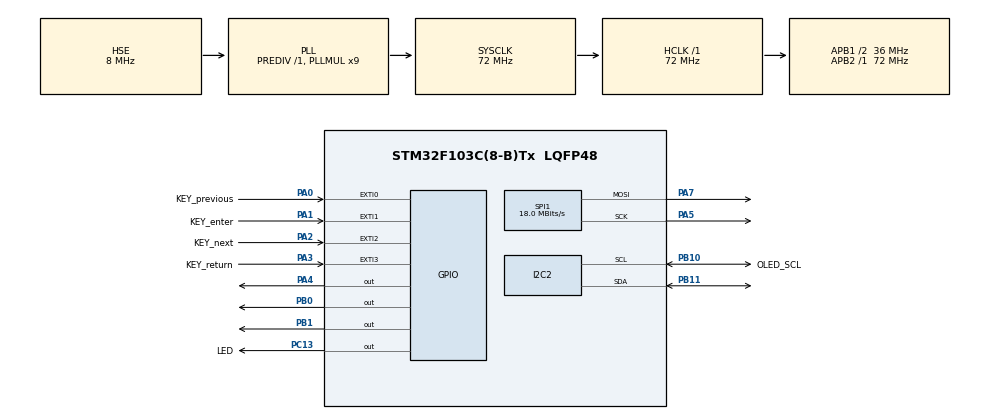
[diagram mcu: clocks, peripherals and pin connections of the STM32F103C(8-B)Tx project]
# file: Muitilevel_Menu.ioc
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Dma.I2C2_TX.1.Direction=DMA_MEMORY_TO_PERIPH
Dma.I2C2_TX.1.Instance=DMA1_Channel4
Dma.I2C2_TX.1.MemDataAlignment=DMA_MDATAALIGN_BYTE
Dma.I2C2_TX.1.MemInc=DMA_MINC_ENABLE
Dma.I2C2_TX.1.Mode=DMA_NORMAL
Dma.I2C2_TX.1.PeriphDataAlignment=DMA_PDATAALIGN_BYTE
Dma.I2C2_TX.1.PeriphInc=DMA_PINC_DISABLE
Dma.I2C2_TX.1.Priority=DMA_PRIORITY_LOW
Dma.Request0=SPI1_TX
Dma.Request1=I2C2_TX
Dma.SPI1_TX.0.Direction=DMA_MEMORY_TO_PERIPH
Dma.SPI1_TX.0.Instance=DMA1_Channel3
Dma.SPI1_TX.0.MemDataAlignment=DMA_MDATAALIGN_BYTE
Dma.SPI1_TX.0.MemInc=DMA_MINC_ENABLE
Dma.SPI1_TX.0.Mode=DMA_NORMAL
Dma.SPI1_TX.0.PeriphDataAlignment=DMA_PDATAALIGN_BYTE
Dma.SPI1_TX.0.PeriphInc=DMA_PINC_DISABLE
Dma.SPI1_TX.0.Priority=DMA_PRIORITY_LOW
I2C2.I2C_Mode=I2C_Fast
Mcu.Family=STM32F1
Mcu.Name=STM32F103C(8-B)Tx
Mcu.Package=LQFP48
NVIC.DMA1_Channel3_IRQn=true\:0\:0\:false\:false\:true\:false\:true\:true
NVIC.DMA1_Channel4_IRQn=true\:0\:0\:false\:false\:true\:false\:true\:true
NVIC.EXTI0_IRQn=true\:15\:0\:true\:false\:true\:true\:true\:true
NVIC.EXTI1_IRQn=true\:15\:0\:true\:false\:true\:true\:true\:true
NVIC.EXTI2_IRQn=true\:15\:0\:true\:false\:true\:true\:true\:true
NVIC.EXTI3_IRQn=true\:15\:0\:true\:false\:true\:true\:true\:true
NVIC.I2C2_ER_IRQn=true\:0\:0\:false\:false\:true\:true\:true\:true
NVIC.I2C2_EV_IRQn=true\:0\:0\:true\:false\:true\:true\:true\:true
NVIC.PriorityGroup=NVIC_PRIORITYGROUP_4
NVIC.SPI1_IRQn=true\:0\:0\:false\:false\:true\:true\:true\:true
PA0-WKUP.GPIO_Label=KEY_previous
PA0-WKUP.GPIO_ModeDefaultEXTI=GPIO_MODE_IT_FALLING
PA0-WKUP.GPIO_PuPd=GPIO_PULLUP
PA0-WKUP.Signal=GPXTI0
PA1.GPIO_Label=KEY_enter
PA1.GPIO_ModeDefaultEXTI=GPIO_MODE_IT_FALLING
PA1.GPIO_PuPd=GPIO_PULLUP
PA1.Signal=GPXTI1
PA13.Mode=Serial_Wire
PA13.Signal=SYS_JTMS-SWDIO
PA14.Mode=Serial_Wire
PA14.Signal=SYS_JTCK-SWCLK
PA2.GPIO_Label=KEY_next
PA2.GPIO_ModeDefaultEXTI=GPIO_MODE_IT_FALLING
PA2.GPIO_PuPd=GPIO_PULLUP
PA2.Signal=GPXTI2
PA3.GPIO_Label=KEY_return
PA3.GPIO_ModeDefaultEXTI=GPIO_MODE_IT_FALLING
PA3.GPIO_PuPd=GPIO_PULLUP
PA3.Signal=GPXTI3
PA4.GPIO_Speed=GPIO_SPEED_FREQ_HIGH
PA4.PinState=GPIO_PIN_RESET
PA4.Signal=GPIO_Output
PA5.Mode=TX_Only_Simplex_Unidirect_Master
PA5.Signal=SPI1_SCK
PA7.Mode=TX_Only_Simplex_Unidirect_Master
PA7.Signal=SPI1_MOSI
PB0.GPIO_Speed=GPIO_SPEED_FREQ_HIGH
PB0.Signal=GPIO_Output
PB1.GPIO_Speed=GPIO_SPEED_FREQ_HIGH
PB1.Signal=GPIO_Output
PB10.GPIO_Label=OLED_SCL
PB10.Mode=I2C
PB10.Signal=I2C2_SCL
PB11.Mode=I2C
PB11.Signal=I2C2_SDA
PC13-TAMPER-RTC.GPIO_Label=LED
PC13-TAMPER-RTC.GPIO_Speed=GPIO_SPEED_FREQ_LOW
PC13-TAMPER-RTC.PinState=GPIO_PIN_SET
PC13-TAMPER-RTC.Signal=GPIO_Output
PD0-OSC_IN.Mode=HSE-External-Oscillator
PD0-OSC_IN.Signal=RCC_OSC_IN
PD1-OSC_OUT.Mode=HSE-External-Oscillator
PD1-OSC_OUT.Signal=RCC_OSC_OUT
ProjectManager.HeapSize=0x200
ProjectManager.StackSize=0x400
ProjectManager.TargetToolchain=MDK-ARM V5
RCC.AHBFreq_Value=72000000
RCC.APB1CLKDivider=RCC_HCLK_DIV2
RCC.APB1Freq_Value=36000000
RCC.APB1TimFreq_Value=72000000
RCC.APB2Freq_Value=72000000
RCC.APB2TimFreq_Value=72000000
RCC.HCLKFreq_Value=72000000
RCC.PLLMUL=RCC_PLL_MUL9
RCC.PLLSourceVirtual=RCC_PLLSOURCE_HSE
RCC.SYSCLKFreq_VALUE=72000000
RCC.SYSCLKSource=RCC_SYSCLKSOURCE_PLLCLK
RCC.USBFreq_Value=72000000
SPI1.BaudRatePrescaler=SPI_BAUDRATEPRESCALER_4
SPI1.CalculateBaudRate=18.0 MBits/s
SPI1.Direction=SPI_DIRECTION_2LINES
SPI1.Mode=SPI_MODE_MASTER
SPI1.VirtualType=VM_MASTER
board=custom

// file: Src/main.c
/* USER CODE BEGIN Header */
/**
  ******************************************************************************
  * @file           : main.c
  * @brief          : Main program body
  ******************************************************************************
  * @attention
  *
  * Copyright (c) 2024 STMicroelectronics.
  * All rights reserved.
  *
  * This software is licensed under terms that can be found in the LICENSE file
  * in the root directory of this software component.
  * If no LICENSE file comes with this software, it is provided AS-IS.
  *
  ******************************************************************************
  */
/* USER CODE END Header */
#include "main.h"
#include "dma.h"
#include "i2c.h"
#include "spi.h"
#include "gpio.h"

/* USER CODE BEGIN Includes */
#include "MuMeStar.h"
/* USER CODE END Includes */

void SystemClock_Config(void);

int main(void)
{

  /* MCU Configuration--------------------------------------------------------*/
  /* Reset of all peripherals, Initializes the Flash interface and the Systick. */
  HAL_Init();
  /* Configure the system clock */
  SystemClock_Config();

  /* Initialize all configured peripherals */
  MX_GPIO_Init();
  MX_DMA_Init();
  MX_I2C2_Init();
  MX_SPI1_Init();

  /* Infinite loop */
  /* USER CODE BEGIN WHILE */

  OLED_Init();
  Multimenu_Init();
  while (1)
  {
    Menu_Handler();
    /* USER CODE END WHILE */

  }
}

void SystemClock_Config(void)
{
  RCC_OscInitTypeDef RCC_OscInitStruct = {0};
  RCC_ClkInitTypeDef RCC_ClkInitStruct = {0};

  /** Initializes the RCC Oscillators according to the specified parameters
  * in the RCC_OscInitTypeDef structure.
  */
  RCC_OscInitStruct.OscillatorType = RCC_OSCILLATORTYPE_HSE;
  RCC_OscInitStruct.HSEState = RCC_HSE_ON;
  RCC_OscInitStruct.HSEPredivValue = RCC_HSE_PREDIV_DIV1;
  RCC_OscInitStruct.HSIState = RCC_HSI_ON;
  RCC_OscInitStruct.PLL.PLLState = RCC_PLL_ON;
  RCC_OscInitStruct.PLL.PLLSource = RCC_PLLSOURCE_HSE;
  RCC_OscInitStruct.PLL.PLLMUL = RCC_PLL_MUL9;
  if (HAL_RCC_OscConfig(&RCC_OscInitStruct) != HAL_OK)
  {
    Error_Handler();
  }

  /** Initializes the CPU, AHB and APB buses clocks
  */
  RCC_ClkInitStruct.ClockType = RCC_CLOCKTYPE_HCLK|RCC_CLOCKTYPE_SYSCLK
                              |RCC_CLOCKTYPE_PCLK1|RCC_CLOCKTYPE_PCLK2;
  RCC_ClkInitStruct.SYSCLKSource = RCC_SYSCLKSOURCE_PLLCLK;
  RCC_ClkInitStruct.AHBCLKDivider = RCC_SYSCLK_DIV1;
  RCC_ClkInitStruct.APB1CLKDivider = RCC_HCLK_DIV2;
  RCC_ClkInitStruct.APB2CLKDivider = RCC_HCLK_DIV1;

  if (HAL_RCC_ClockConfig(&RCC_ClkInitStruct, FLASH_LATENCY_2) != HAL_OK)
  {
    Error_Handler();
  }
}

void Error_Handler(void)
{
  __disable_irq();
  while (1)
  {
  }
}
